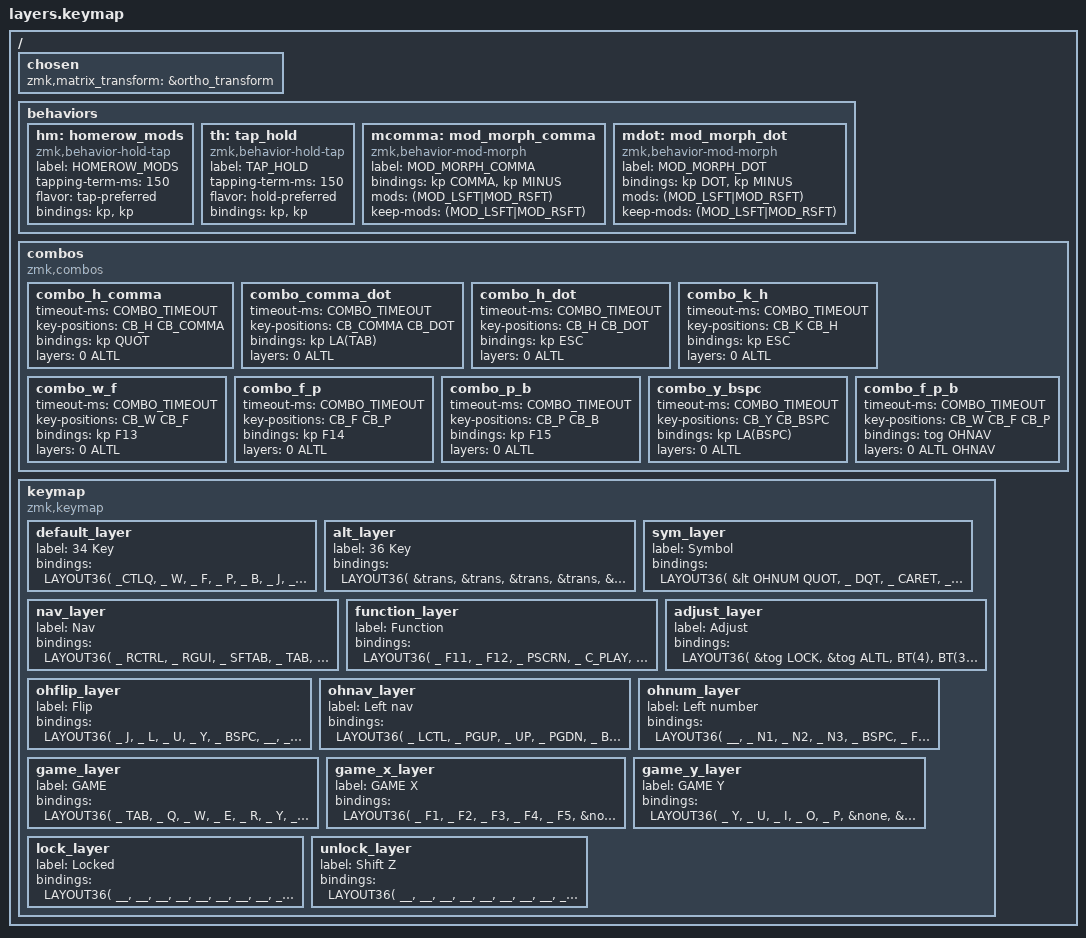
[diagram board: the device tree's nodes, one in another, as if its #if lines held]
#include <behaviors.dtsi>
#include <dt-bindings/zmk/keys.h>
#include <dt-bindings/zmk/bt.h>
#include <dt-bindings/zmk/outputs.h>

// https://zmk.dev/docs/codes/keyboard-keypad
#define ALTL   1
#define SYM    2
#define NAV    3
#define FUN    4
#define ADJ    5
#define OHFLIP 6
#define OHNAV  7
#define OHNUM  8
#define GAME   9
#define GAMEX  10
#define GAMEY  11
#define LOCK   12
#define ULOC   13

#define NTAB LC(PGDN) /* Next tab */
#define PTAB LC(PGUP) /* Previous tab */
#define SFTAB LS(TAB) /* Shift-tab */

#define BT(n) &bt BT_SEL n
#define BT_BLE &out OUT_BLE
#define BT_USB &out OUT_USB
#define BT_TOG &out OUT_TOG

/* Shorthand */
#define _ &kp
#define __ &none

/* Complex keys */
#define _CTLQ &hm LCTL Q /* Q (tap), ctrl (hold) */
#define _CENT &th LCTL RET /* Enter (tap), ctrl (hold) */
#define _BSLH &lt ADJ BSLH /* \ (tap), ADJ (hold) */

#define COMBO_TIMEOUT 30

/ {
#ifdef TECHNIKABLE
  chosen {
     // zmk,matrix_transform = &dual_2u_transform;
     zmk,matrix_transform = &ortho_transform;
  };
#endif

  behaviors {
    hm: homerow_mods { // Letter mods
      compatible = "zmk,behavior-hold-tap";
      label = "HOMEROW_MODS";
      #binding-cells = <2>;
      tapping-term-ms = <150>;
      flavor = "tap-preferred";
      bindings = <&kp>, <&kp>;
    };
    th: tap_hold { // Other mods (enter)
      compatible = "zmk,behavior-hold-tap";
      label = "TAP_HOLD";
      #binding-cells = <2>;
      tapping-term-ms = <150>;
      flavor = "hold-preferred";
      bindings = <&kp>, <&kp>;
    };
    mcomma: mod_morph_comma {
      compatible = "zmk,behavior-mod-morph";
      label = "MOD_MORPH_COMMA";
      #binding-cells = <0>;
      bindings = <&kp COMMA>, <&kp MINUS>; // [sft ,] ─› [_]
      mods = <(MOD_LSFT|MOD_RSFT)>;
      keep-mods = <(MOD_LSFT|MOD_RSFT)>;
    };
    mdot: mod_morph_dot {
      compatible = "zmk,behavior-mod-morph";
      label = "MOD_MORPH_DOT";
      #binding-cells = <0>;
      bindings = <&kp DOT>, <&kp MINUS>; // [sft .] ─› [_]
      mods = <(MOD_LSFT|MOD_RSFT)>;
      keep-mods = <(MOD_LSFT|MOD_RSFT)>;
    };
  };

  combos {
    compatible = "zmk,combos";
    combo_h_comma {
      timeout-ms = <COMBO_TIMEOUT>;
      key-positions = <CB_H CB_COMMA>; // [ k h , . ^ ]
      bindings = <&kp QUOT>; //               └─┴──› '
      layers = <0 ALTL>;
    };
    combo_comma_dot {
      timeout-ms = <COMBO_TIMEOUT>;
      key-positions = <CB_COMMA CB_DOT>; // [ k h , . ^ ]
      bindings = <&kp LA(TAB)>; //                └─┴──› alt-tab
      layers = <0 ALTL>;
    };
    combo_h_dot {
      timeout-ms = <COMBO_TIMEOUT>;
      key-positions = <CB_H CB_DOT>; // [ k h , . ^ ]
      bindings = <&kp ESC>; //              └───┴──› esc
      layers = <0 ALTL>;
    };
    combo_k_h {
      timeout-ms = <COMBO_TIMEOUT>;
      key-positions = <CB_K CB_H>; // [ k h , . ^ ]
      bindings = <&kp ESC>; //          └─┴──› esc
      layers = <0 ALTL>;
    };
    #if defined(CB_W) && defined(CB_F)
      combo_w_f { // [wf] - f14 / XF86Launch5 (mouse click)
        timeout-ms = <COMBO_TIMEOUT>;
        key-positions = <CB_W CB_F>;
        bindings = <&kp F13>;
        layers = <0 ALTL>;
      };
    #endif

    #if defined(CB_F) && defined(CB_P)
      combo_f_p { // [fp] - f13 / XF86Tools (mouse click)
        timeout-ms = <COMBO_TIMEOUT>;
        key-positions = <CB_F CB_P>;
        bindings = <&kp F14>;
        layers = <0 ALTL>;
      };
    #endif

    #if defined(CB_P) && defined(CB_B)
      combo_p_b { // [pb] - f15 / XF86Launch6 (mouse click)
        timeout-ms = <COMBO_TIMEOUT>;
        key-positions = <CB_P CB_B>;
        bindings = <&kp F15>;
        layers = <0 ALTL>;
      };
    #endif

    #if defined(CB_Y) && defined(CB_BSPC)
      combo_y_bspc {
        timeout-ms = <COMBO_TIMEOUT>;
        key-positions = <CB_Y CB_BSPC>;
        bindings = <&kp LA(BSPC)>;
        layers = <0 ALTL>;
      };
    #endif

    #if defined(CB_W) && defined(CB_F) && defined(CB_P)
      combo_f_p_b { // [wfp] - toggle one-hand
        timeout-ms = <COMBO_TIMEOUT>;
        key-positions = <CB_W CB_F CB_P>;
        bindings = <&tog OHNAV>;
        layers = <0 ALTL OHNAV>;
      };
    #endif
  };

  keymap {
    compatible = "zmk,keymap";

    default_layer {
      label = "34 Key";
      // ┌─────────────────────┐┌─────────────────────┐
      // │ q^  w   f   p   b   ││ j   l   u   y   bks │ Colemak DH
      // │ a   r   s   t   g   ││ m   n   e   i   o   │
      // │ z   x   c   d   v   ││ k   h   ,_  ._  ent^│ (ent-ctrl)
      // └─────────────────────┤├─────────────────────┘
      //         │ gui SYM ↑   ││ ──  NAV alt │
      //         └─────────────┘└─────────────┘
      bindings = < LAYOUT36(
        _CTLQ,        _ W, _ F,    _ P,     _ B,    /**/  _ J,     _ L,     _ U,            _ Y,          _ BSPC,
        _ A,          _ R, _ S,    _ T,     _ G,    /**/  _ M,     _ N,     _ E,            _ I,          _ O,
        &lt OHFLIP Z, _ X, _ C,    _ D,     _ V,    /**/  _ K,     _ H,     &hm LGUI COMMA, &hm LALT DOT, _CENT
        /*,           */,  _ LGUI, &mo SYM, _ LSFT, /**/  _ SPACE, &mo NAV, _ LALT
      ) >;
    };

    alt_layer {
      label = "36 Key";
      bindings = < LAYOUT36(
        &trans, &trans, &trans, &trans, &trans, /**/ &trans, &trans, &trans,  &trans, &trans,
        &trans, &trans, &trans, &trans, &trans, /**/ &trans, &trans, &trans,  &trans, &trans,
        _ Z,    &trans, &trans, &trans, &trans, /**/ &trans, &trans, &mcomma, &mdot,  &trans
        /*,     */,     &trans, &trans, &trans, /**/ &trans, &trans, &trans
      ) >;
    };

    sym_layer {
      label = "Symbol";
      // ┌─────────────────────┐┌─────────────────────┐
      // │ '⁺  "   ^   ?   `   ││ [   <   =   >   ]   │ Symbols
      // │ !⁺  @   #   $   %   ││ {   (   :   )   }   │
      // │ \⁺  ~   |   ;   &   ││ /   *   -   +   _   │ ⁺ = layer tap
      // └───────┐─────────────││─────────────┌───────┘
      //         │ ·   ▓▓  ADJ ││ ·   FUN ralt│
      //         └─────────────┘└─────────────┘
      bindings = < LAYOUT36(
        &lt OHNUM QUOT, _ DQT,   _ CARET, _ QMARK, _ GRAVE, /**/ _ LBKT,  _ LT,    _ EQUAL, _ GT,   _ RBKT,
        &lt OHNAV EXCL, _ AT,    _ HASH,  _ DLLR,  _ PRCNT, /**/ _ LBRC,  _ LPAR,  _ COLON, _ RPAR, _ RBRC,
        &lt ADJ BSLH,   _ TILDE, _ PIPE,  _ SEMI,  _ AMPS,  /**/ _ SLASH, _ STAR,  _ MINUS, _ PLUS, _ UNDER
        /*,             */,      &trans,  &mo FUN, &mo ADJ, /**/ _ SPACE, &mo FUN, _ RALT
      ) >;
    };

    nav_layer {
      label = "Nav";
      // ┌─────────────────────┐┌─────────────────────┐
      // │ ctl gui ⇤   ⇥   alt ││ ,   hom ▲   end del │
      // │ 1   2   3   4   5   ││ .   ◀   ▼   ▶   ent │
      // │ 6   7   8   9   0   ││ ins p↑  p↓  esc ctl │
      // └───────┐ ·   sym ·   ││ spc ▓▓  ralt┌───────┘
      //         └─────────────┘└─────────────┘
      bindings = < LAYOUT36(
        _ RCTRL, _ RGUI, _ SFTAB, _ TAB,  _ LALT, /**/ _ COMMA, _   HOME, _ UP,   _ END,   _ DEL,
        _ N1,    _ N2,   _ N3,    _ N4,   _ N5,   /**/ _ DOT,   _   LEFT, _ DOWN, _ RIGHT, _ RET,
        _ N6,    _ N7,   _ N8,    _ N9,   _ N0,   /**/ _ INS,   _   PGUP, _ PGDN, _ ESC,   _ LCTL
        /*,      */,     &trans,  &trans, &trans, /**/ _ SPACE, &mo FUN,  _ RALT
      ) >;
    };

    function_layer {
      label = "Function";
      // ┌─────────────────────┐┌─────────────────────┐
      // │ f11 f12 psc ply nxt ││ .   .   .   .   .   │
      // │ f1  f2  f3  f4  f5  ││ .   .   .   .   .   │
      // │ f6  f7  f8  f9  f10 ││ cap v-  v+  b⁻  b⁺  │
      // └───────┐ ·   ·   ──  ││ ──  ▓▓  ·   ┌───────┘
      //         └─────────────┘└─────────────┘
      bindings = < LAYOUT36(
        _ F11, _ F12, _ PSCRN, _ C_PLAY, _ C_NEXT, /**/ _ C_VOL_UP, __,         __,         __,         __,
        _ F1,  _ F2,  _ F3,    _ F4,     _ F5,     /**/ _ C_VOL_DN, __,         __,         __,         __,
        _ F6,  _ F7,  _ F8,    _ F9,     _ F10,    /**/ _ CAPS,     _ C_VOL_DN, _ C_VOL_UP, _ C_BRI_DN, _ C_BRI_UP
        /*,    */,    &trans,  &trans,   &trans,   /**/ &trans,     &trans,     &trans
      ) >;
    };

    adjust_layer {
      label = "Adjust";
      // ┌─────────────────────┐ ┌─────────────────────┐
      // │lock alt b5  b4  BOOT│ │ .   .   .   .   .   │
      // │game b3  b2  b1  .   │ │ .   b3  b2  b1  .   │
      // │━━   tog usb bt  clr │ │ .   tog usb bt  .   │
      // └───────┐ ·   ·   ▓▓  │ │ tog bt  usb ┌───────┘
      //         └─────────────┘ └─────────────┘
      bindings = < LAYOUT36(
        &tog LOCK, &tog ALTL,    BT(4),  BT(3),  &bootloader, /**/ __,  __,           __,     __,     __,
        &tog GAME, BT(2),        BT(1),  BT(0),  __,          /**/ __,  BT(2),        BT(1),  BT(0),  __,
        __,        &out OUT_TOG, BT_USB, BT_BLE, &bt BT_CLR,  /**/ __,  &out OUT_TOG, BT_USB, BT_BLE, &to OHNAV
        /*,        */,           &trans, &trans, __,          /**/  __, __,           __
      ) >;
    };

    ohflip_layer { // One-hand flip
      label = "Flip";
      // ┌─────────────────────┐ ┌─────────────────────┐
      // │ j   l   u   y   bks │ │ .   .   U   .   .   │
      // │ m   n   e   i   o   │ │ .   L   D   R   .   │
      // │ ━━  h   ,⁺  .⁺  k   │ │ .   pu  pd  .   .   │
      // └───────┐ ctl nav spc │ │ .   .   .   ┌───────┘
      //         └─────────────┘ └─────────────┘
      bindings = < LAYOUT36(
        _ J, _ L, _ U,            _ Y,          _ BSPC,  /**/ __, __,     _ UP,   __,      __,
        _ M, _ N, _ E,            _ I,          _ O,     /**/ __, _ LEFT, _ DOWN, _ RIGHT, __,
        __,  _ H, &hm LALT COMMA, &hm LGUI DOT, _ K,     /**/ __, _ PGUP, _ PGDN, __,      __
        /*,  */,  _ LCTL,         &mo OHNAV,    _ SPACE, /**/ __, __,     __
      ) >;
    };

    ohnav_layer { // One-hand nav [A]
      label = "Left nav";
      // ┌─────────────────────┐ ┌─────────────────────┐
      // │ ctl pu  U   pd  bs  │ │ .   .   U   .   .   │
      // │ .   L   D   R   ent │ │ .   L   D   R   .   │
      // │ .   sft alt gui esc │ │ .   pu  pd  .   off │
      // └───────┐ .   ━━  spc │ │ .   .   .   ┌───────┘
      //         └─────────────┘ └─────────────┘
      bindings = < LAYOUT36(
        _ LCTL, _ PGUP, _ UP,   _ PGDN,  _ BSPC,  /**/ __, __,     _ UP,   __,      __,
        __,     _ LEFT, _ DOWN, _ RIGHT, _ RET,   /**/ __, _ LEFT, _ DOWN, _ RIGHT, __,
        _ LCTL, _ LSFT, _ LALT, _ LGUI,  _ ESC,   /**/ __, _ PGUP, _ PGDN, __,      &tog OHNAV
        /*,     */,     __,     __,      _ SPACE, /**/ __, __,     __
      ) >;
    };

    ohnum_layer { // One-hand number [Q]
      label = "Left number";
      // ┌─────────────────────┐ ┌─────────────────────┐
      // │ ━━  1   2   3   bks │ │                     │
      // │ .   4   5   6   ret │ │                     │
      // │ .   7   8   9   .   │ │                     │
      // └───────┐ .   .   .   │ │             ┌───────┘
      //         └─────────────┘ └─────────────┘
      bindings = < LAYOUT36(
        __, _ N1, _ N2, _ N3, _ BSPC,  /**/  _ F14, _ HOME, _ UP,   _ END,   _ DEL,
        __, _ N4, _ N5, _ N6, _ RET,   /**/  _ F15, _ LEFT, _ DOWN, _ RIGHT, _ RET,
        __, _ N7, _ N8, _ N9, _ N0,    /**/  _ F13, _ PGUP, _ PGDN, _ ESC,   _ LCTL
        /*, */,   __,   __,   _ N0,    /**/ __,     __,     __
      ) >;
    };

    game_layer {
      label = "GAME";
      // ┌─────────────────────┐ ┌─────────────────────┐
      // │ tab q   w   e   r   │ │ y   u   i   o   p   │ Game
      // │ sft a   s   d   f   │ │ t   j   k   l   ent │
      // │ ctl 1   2   3   4   │ │ n   m           esc │
      // └───────┐ ▲Y  ▲X  spc │ │ spc XX exit ┌───────┘
      // ┌─────────────────────┐ ┌─────────────────────┐
      // │ f1  f2  f3  f4  f5  │ │         ↑       bs  │ X
      // │ 5   6   7   g   h   │ │     ←   ↓   →   ent │
      // │ z   x   c   v   b   │ │                 esc │
      // └───────┐     ━━  alt │ │        exit ┌───────┘
      // ┌─────────────────────┐ ┌─────────────────────┐
      // │ y   u   i   o   p   │ │         ↑       bs  │ Y
      // │ t   j   k   l   ent │ │     ←   ↓   →   ent │
      // │ n   m   c   v   esc │ │                 esc │
      // └───────┐ ━━          │ │        exit ┌───────┘
      //         └─────────────┘ └─────────────┘

      bindings = < LAYOUT36(
        _ TAB,     _ Q,       _ W,   _ E,        _ R,       /**/ _ Y, _ U, _ I, _ O, _ P,
        _ LSFT,    _ A,       _ S,   _ D,        _ F,       /**/ _ T, _ J, _ K, _ L, _ RET,
        _ LCTL,    _ N1,      _ N2,  _ N3,       _ N4,      /**/ _ N, _ M, __,  __,  _ ESC,
        &mo GAMEY, &mo GAMEX, _ SPC, /**/ _ SPC, &mo GAMEX, &tog GAME
      ) >;
    };

    game_x_layer {
      label = "GAME X";
      bindings = < LAYOUT36(
        _ F1, _ F2, _ F3,  _ F4,  _ F5,     &none, &none,  _ UP,   &none,   _ BSPC,
        _ N5, _ N6, _ N7,  _ G,   _ H,      &none, _ LEFT, _ DOWN, _ RIGHT, _ RET,
        _ Z,  _ X,  _ C,   _ V,   _ B,      &none, &none,  &none,  &none,   _ ESC
        /*,   */,   &none, &none, &kp LALT, &none, &none,  &tog GAME
      ) >;
    };

    game_y_layer {
      label = "GAME Y";
      bindings = < LAYOUT36(
        _ Y, _ U, _ I,     _ O,   _ P,   &none, &none,  _ UP,   &none,   _ BSPC,
        _ T, _ J, _ K,     _ L,   _ RET, &none, _ LEFT, _ DOWN, _ RIGHT, _ RET,
        _ N, _ M, _ COMMA, _ DOT, _ ESC, &none, &none,  &none,  &none,   _ ESC
        /*,  */,  &none,   &none, &none, &none, &none,  &tog GAME
      ) >;
    };

    lock_layer { // Lock
      label = "Locked";
      bindings = < LAYOUT36(
        __,       __, __, __, __, __, __, __, __, &tog LOCK,
        __,       __, __, __, __, __, __, __, __, __,
        &mo ULOC, __, __, __, __, __, __, __, __, __,
        /**/ __, __, &mo ULOC, /**/ __, __, &tog LOCK
      ) >;
    };

    unlock_layer { // Unlock
      label = "Shift Z";
      bindings = < LAYOUT36(
        __,       __, __, __, __, __, __, __, __, __,
        __,       __, __, __, __, __, __, __, __, __,
        &tog LOCK, __, __, __, __, __, __, __, __, __,
        /**/ __, __, &tog LOCK, /**/ __, __, __
      ) >;
    };
  };
};

// vim:ft=c:fdm=indent
